# PIC32MZ1064DAH176 register map
Vendor: Microchip
Registers are 32-bit, read-write, reset 0x0 unless marked. A register's access mark holds for its fields unless they carry their own. Addresses are absolute, and some are shared; only a register's first bit layout is shown; [hi:lo] are bit positions; {n}, {i} and the like mark numbered series.

## CMP1
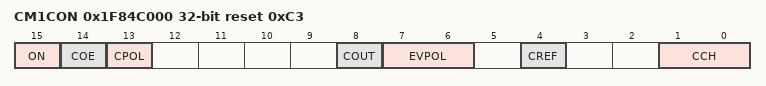
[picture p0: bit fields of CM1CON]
0x1F84C000 CM1CON reset 0xC3
  [15] ON, [14] COE, [13] CPOL, [8] COUT, [7:6] EVPOL, [4] CREF, [1:0] CCH

## CMP2
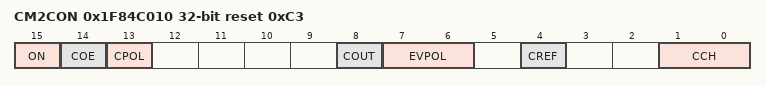
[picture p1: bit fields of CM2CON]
0x1F84C010 CM2CON reset 0xC3
  [15] ON, [14] COE, [13] CPOL, [8] COUT, [7:6] EVPOL, [4] CREF, [1:0] CCH

## cmp_control_pb
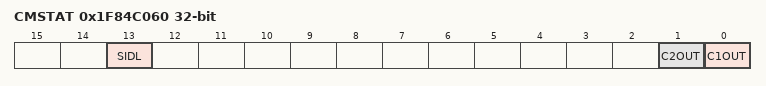
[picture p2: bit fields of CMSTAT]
0x1F84C060 CMSTAT
  [13] SIDL, [1] C2OUT ro, [0] C1OUT ro

## CTMU
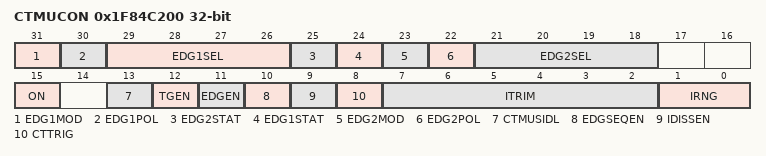
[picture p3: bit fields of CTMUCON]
0x1F84C200 CTMUCON
  [31] EDG1MOD, [30] EDG1POL, [29:26] EDG1SEL, [25] EDG2STAT, [24] EDG1STAT, [23] EDG2MOD, [22] EDG2POL, [21:18] EDG2SEL, [15] ON, [13] CTMUSIDL, [12] TGEN, [11] EDGEN, [10] EDGSEQEN, [9] IDISSEN, [8] CTTRIG, [7:2] ITRIM, [1:0] IRNG

## gpio_ports_upb
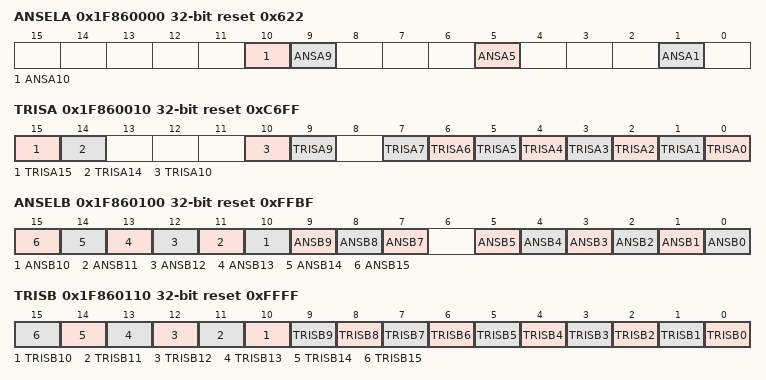
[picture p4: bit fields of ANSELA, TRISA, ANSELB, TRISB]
0x1F860000 ANSELA reset 0x622
  [10] ANSA10, [9] ANSA9, [5] ANSA5, [1] ANSA1
0x1F860010 TRISA reset 0xC6FF
  [15] TRISA15, [14] TRISA14, [10] TRISA10, [9] TRISA9, [n] TRISA{n} (n=0..7)
0x1F860100 ANSELB reset 0xFFBF
  [n] ANSB{n} (n=7..15), [n] ANSB{n} (n=0..5)
0x1F860110 TRISB reset 0xFFFF
  [n] TRISB{n} (n=0..15)
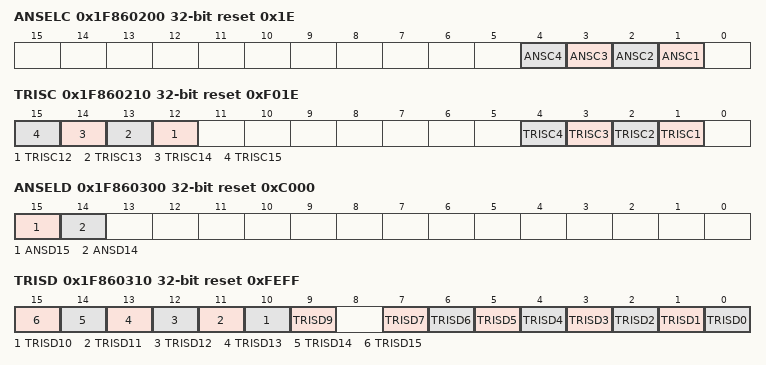
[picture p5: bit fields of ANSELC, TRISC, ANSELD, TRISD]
0x1F860200 ANSELC reset 0x1E
  [n] ANSC{n} (n=1..4)
0x1F860210 TRISC reset 0xF01E
  [n] TRISC{n} (n=12..15), [n] TRISC{n} (n=1..4)
0x1F860300 ANSELD reset 0xC000
  [15] ANSD15, [14] ANSD14
0x1F860310 TRISD reset 0xFEFF
  [n] TRISD{n} (n=9..15), [n] TRISD{n} (n=0..7)
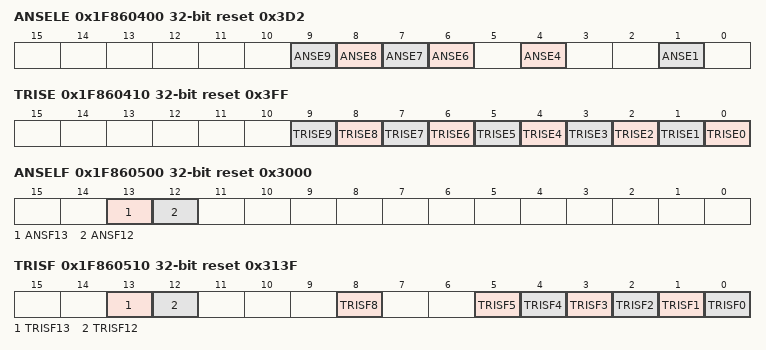
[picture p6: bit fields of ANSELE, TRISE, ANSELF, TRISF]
0x1F860400 ANSELE reset 0x3D2
  [n] ANSE{n} (n=6..9), [4] ANSE4, [1] ANSE1
0x1F860410 TRISE reset 0x3FF
  [n] TRISE{n} (n=0..9)
0x1F860500 ANSELF reset 0x3000
  [13] ANSF13, [12] ANSF12
0x1F860510 TRISF reset 0x313F
  [13] TRISF13, [12] TRISF12, [8] TRISF8, [n] TRISF{n} (n=0..5)
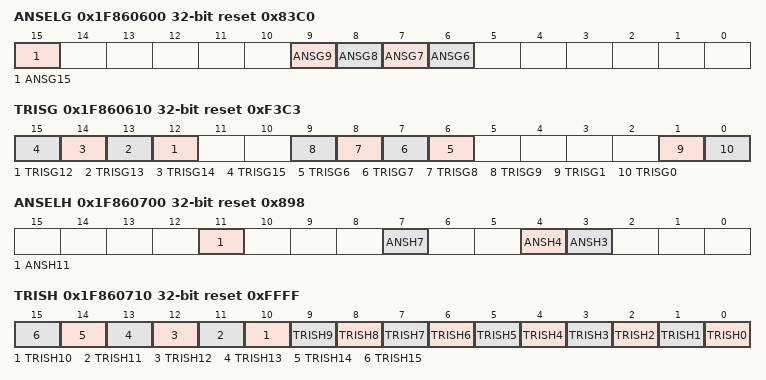
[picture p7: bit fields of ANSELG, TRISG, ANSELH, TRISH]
0x1F860600 ANSELG reset 0x83C0
  [15] ANSG15, [n] ANSG{n} (n=6..9)
0x1F860610 TRISG reset 0xF3C3
  [n] TRISG{n} (n=12..15), [n] TRISG{n} (n=6..9), [1] TRISG1, [0] TRISG0
0x1F860700 ANSELH reset 0x898
  [11] ANSH11, [7] ANSH7, [4] ANSH4, [3] ANSH3
0x1F860710 TRISH reset 0xFFFF
  [n] TRISH{n} (n=0..15)
0x1F860800 ANSELJ reset 0x4
  [2] ANSJ2
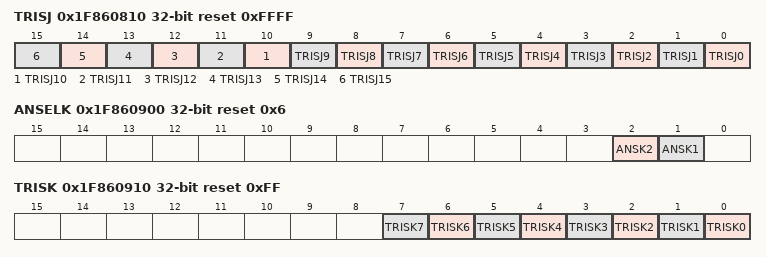
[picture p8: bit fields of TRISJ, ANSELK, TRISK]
0x1F860810 TRISJ reset 0xFFFF
  [n] TRISJ{n} (n=0..15)
0x1F860900 ANSELK reset 0x6
  [2] ANSK2, [1] ANSK1
0x1F860910 TRISK reset 0xFF
  [n] TRISK{n} (n=0..7)

## PORTA
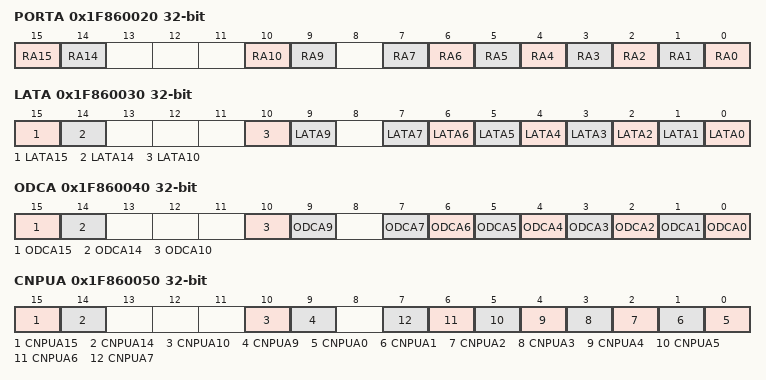
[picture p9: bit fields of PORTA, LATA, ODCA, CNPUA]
0x1F860020 PORTA reset not defined — (power-on value ----------------xx---xx-xxxxxxxx)
  [15] RA15, [14] RA14, [10] RA10, [9] RA9, [n] RA{n} (n=0..7)
0x1F860030 LATA reset not defined — (power-on value ----------------xx---xx-xxxxxxxx)
  [15] LATA15, [14] LATA14, [10] LATA10, [9] LATA9, [n] LATA{n} (n=0..7)
0x1F860040 ODCA
  [15] ODCA15, [14] ODCA14, [10] ODCA10, [9] ODCA9, [n] ODCA{n} (n=0..7)
0x1F860050 CNPUA
  [15] CNPUA15, [14] CNPUA14, [10] CNPUA10, [9] CNPUA9, [n] CNPUA{n} (n=0..7)
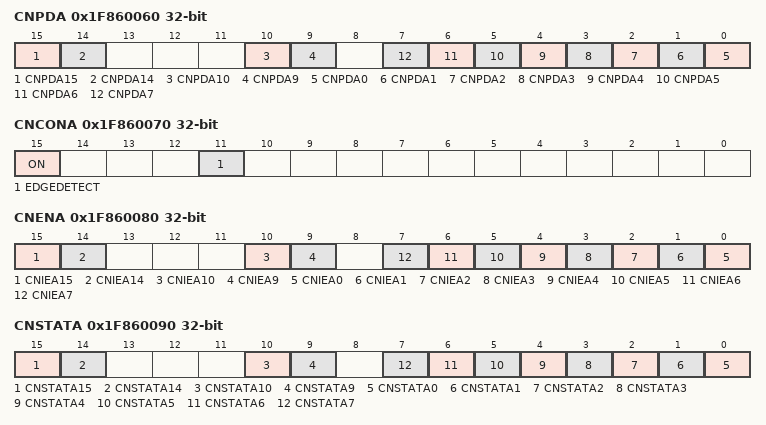
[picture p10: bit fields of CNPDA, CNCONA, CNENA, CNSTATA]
0x1F860060 CNPDA
  [15] CNPDA15, [14] CNPDA14, [10] CNPDA10, [9] CNPDA9, [n] CNPDA{n} (n=0..7)
0x1F860070 CNCONA
  [15] ON, [11] EDGEDETECT
0x1F860080 CNENA
  [15] CNIEA15, [14] CNIEA14, [10] CNIEA10, [9] CNIEA9, [n] CNIEA{n} (n=0..7)
0x1F860090 CNSTATA
  [15] CNSTATA15, [14] CNSTATA14, [10] CNSTATA10, [9] CNSTATA9, [n] CNSTATA{n} (n=0..7)
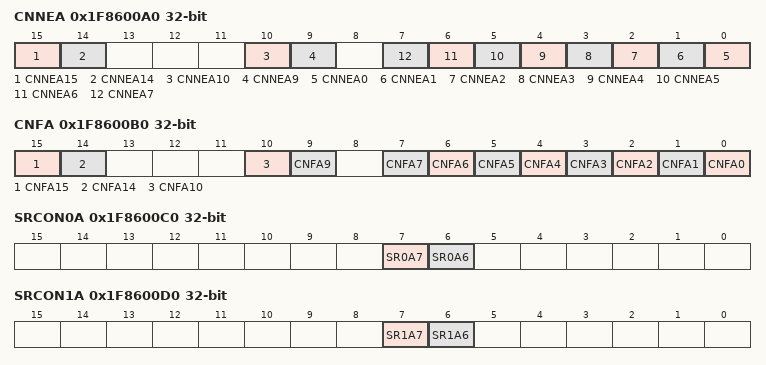
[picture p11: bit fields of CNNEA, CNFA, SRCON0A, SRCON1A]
0x1F8600A0 CNNEA
  [15] CNNEA15, [14] CNNEA14, [10] CNNEA10, [9] CNNEA9, [n] CNNEA{n} (n=0..7)
0x1F8600B0 CNFA
  [15] CNFA15, [14] CNFA14, [10] CNFA10, [9] CNFA9, [n] CNFA{n} (n=0..7)
0x1F8600C0 SRCON0A
  [7] SR0A7, [6] SR0A6
0x1F8600D0 SRCON1A
  [7] SR1A7, [6] SR1A6

## PORTB
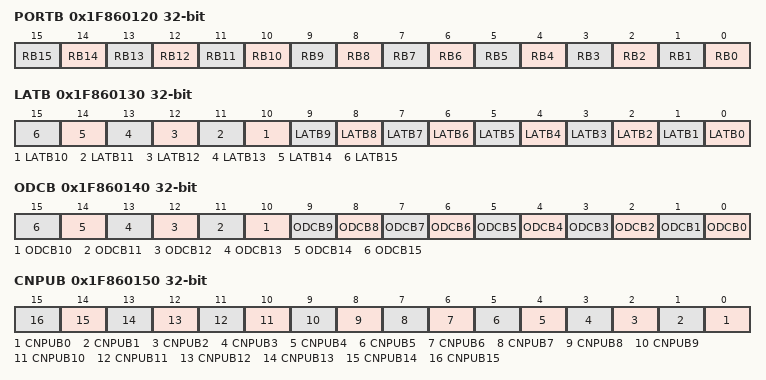
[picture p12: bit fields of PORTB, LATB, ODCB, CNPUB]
0x1F860120 PORTB reset not defined — (power-on value ----------------xxxxxxxxxxxxxxxx)
  [n] RB{n} (n=0..15)
0x1F860130 LATB reset not defined — (power-on value ----------------xxxxxxxxxxxxxxxx)
  [n] LATB{n} (n=0..15)
0x1F860140 ODCB
  [n] ODCB{n} (n=0..15)
0x1F860150 CNPUB
  [n] CNPUB{n} (n=0..15)
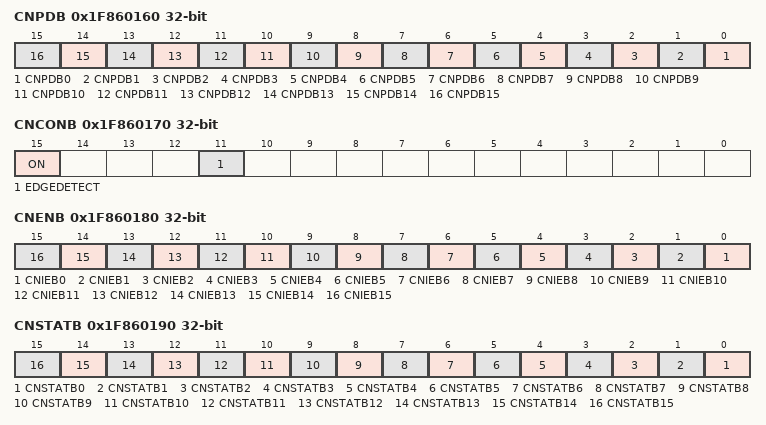
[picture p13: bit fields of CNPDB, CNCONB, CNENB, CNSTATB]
0x1F860160 CNPDB
  [n] CNPDB{n} (n=0..15)
0x1F860170 CNCONB
  [15] ON, [11] EDGEDETECT
0x1F860180 CNENB
  [n] CNIEB{n} (n=0..15)
0x1F860190 CNSTATB
  [n] CNSTATB{n} (n=0..15)
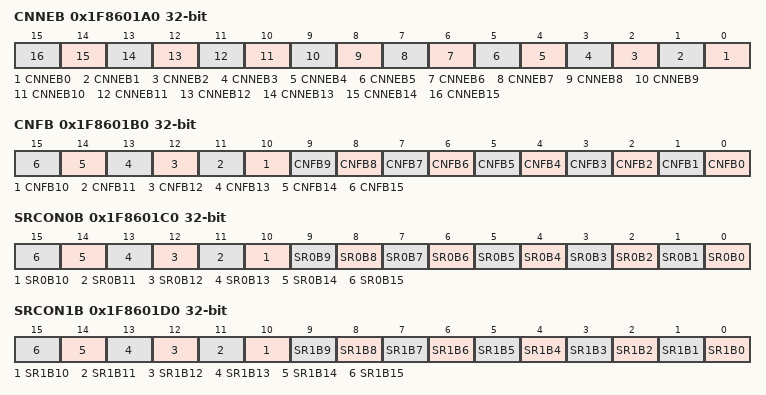
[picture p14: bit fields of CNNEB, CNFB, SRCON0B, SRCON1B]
0x1F8601A0 CNNEB
  [n] CNNEB{n} (n=0..15)
0x1F8601B0 CNFB
  [n] CNFB{n} (n=0..15)
0x1F8601C0 SRCON0B
  [n] SR0B{n} (n=0..15)
0x1F8601D0 SRCON1B
  [n] SR1B{n} (n=0..15)
